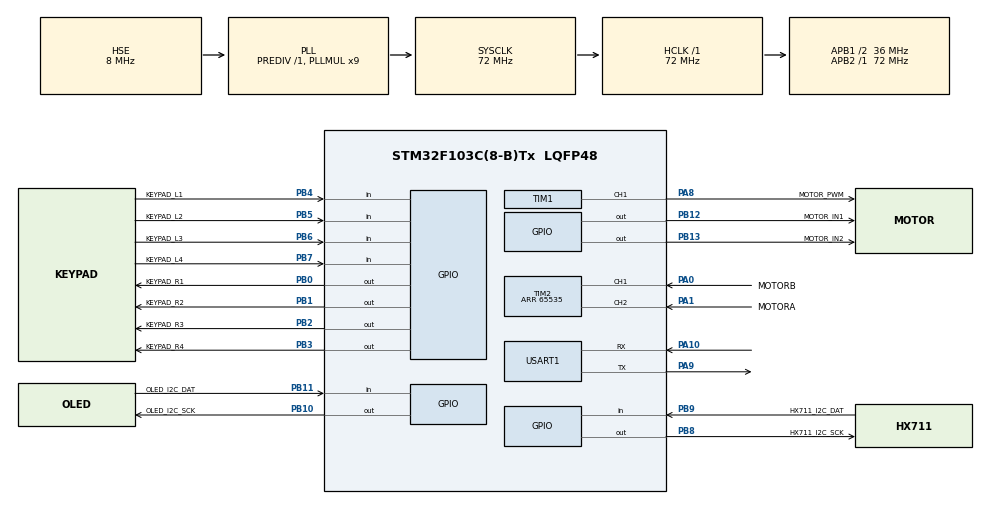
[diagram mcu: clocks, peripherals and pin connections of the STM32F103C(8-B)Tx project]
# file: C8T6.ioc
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Mcu.Family=STM32F1
Mcu.Name=STM32F103C(8-B)Tx
Mcu.Package=LQFP48
NVIC.PriorityGroup=NVIC_PRIORITYGROUP_4
PA0-WKUP.GPIO_Label=MOTORB
PA0-WKUP.Signal=S_TIM2_CH1_ETR
PA1.GPIO_Label=MOTORA
PA1.Signal=S_TIM2_CH2
PA10.Mode=Asynchronous
PA10.Signal=USART1_RX
PA13.Mode=Serial_Wire
PA13.Signal=SYS_JTMS-SWDIO
PA14.Mode=Serial_Wire
PA14.Signal=SYS_JTCK-SWCLK
PA8.GPIO_Label=MOTOR_PWM
PA8.Signal=S_TIM1_CH1
PA9.Mode=Asynchronous
PA9.Signal=USART1_TX
PB0.GPIO_Label=KEYPAD_R1
PB0.GPIO_PuPd=GPIO_PULLDOWN
PB0.Signal=GPIO_Output
PB1.GPIO_Label=KEYPAD_R2
PB1.GPIO_PuPd=GPIO_PULLDOWN
PB1.Signal=GPIO_Output
PB10.GPIO_Label=OLED_I2C_SCK
PB10.Signal=GPIO_Output
PB11.GPIO_Label=OLED_I2C_DAT 
PB11.GPIO_PuPd=GPIO_NOPULL
PB11.Signal=GPIO_Input
PB12.GPIO_Label=MOTOR_IN1
PB12.GPIO_PuPd=GPIO_PULLUP
PB12.Signal=GPIO_Output
PB13.GPIO_Label=MOTOR_IN2
PB13.GPIO_PuPd=GPIO_PULLUP
PB13.Signal=GPIO_Output
PB2.GPIO_Label=KEYPAD_R3
PB2.GPIO_PuPd=GPIO_PULLDOWN
PB2.Signal=GPIO_Output
PB3.GPIO_Label=KEYPAD_R4
PB3.GPIO_PuPd=GPIO_PULLDOWN
PB3.Signal=GPIO_Output
PB4.GPIO_Label=KEYPAD_L1
PB4.GPIO_PuPd=GPIO_PULLDOWN
PB4.Signal=GPIO_Input
PB5.GPIO_Label=KEYPAD_L2
PB5.GPIO_PuPd=GPIO_PULLDOWN
PB5.Signal=GPIO_Input
PB6.GPIO_Label=KEYPAD_L3
PB6.GPIO_PuPd=GPIO_PULLDOWN
PB6.Signal=GPIO_Input
PB7.GPIO_Label=KEYPAD_L4
PB7.GPIO_PuPd=GPIO_PULLDOWN
PB7.Signal=GPIO_Input
PB8.GPIO_Label=HX711_I2C_SCK 
PB8.Signal=GPIO_Output
PB9.GPIO_Label=HX711_I2C_DAT 
PB9.Signal=GPIO_Input
PD0-OSC_IN.Mode=HSE-External-Oscillator
PD0-OSC_IN.Signal=RCC_OSC_IN
PD1-OSC_OUT.Mode=HSE-External-Oscillator
PD1-OSC_OUT.Signal=RCC_OSC_OUT
ProjectManager.HeapSize=0x200
ProjectManager.StackSize=0x400
ProjectManager.TargetToolchain=MDK-ARM V5
RCC.AHBFreq_Value=72000000
RCC.APB1CLKDivider=RCC_HCLK_DIV2
RCC.APB1Freq_Value=36000000
RCC.APB1TimFreq_Value=72000000
RCC.APB2Freq_Value=72000000
RCC.APB2TimFreq_Value=72000000
RCC.HCLKFreq_Value=72000000
RCC.PLLMUL=RCC_PLL_MUL9
RCC.PLLSourceVirtual=RCC_PLLSOURCE_HSE
RCC.SYSCLKFreq_VALUE=72000000
RCC.SYSCLKSource=RCC_SYSCLKSOURCE_PLLCLK
RCC.USBFreq_Value=72000000
SH.S_TIM1_CH1.0=TIM1_CH1,PWM Generation1 CH1
SH.S_TIM2_CH1_ETR.0=TIM2_CH1,Encoder_Interface
SH.S_TIM2_CH2.0=TIM2_CH2,Encoder_Interface
TIM1.Channel-PWM\ Generation1\ CH1=TIM_CHANNEL_1
TIM1.Period=1000
TIM1.Prescaler=1
TIM2.EncoderMode=TIM_ENCODERMODE_TI12
TIM2.IC1Filter=6
TIM2.IC2Filter=6
TIM2.Period=65535
USART1.VirtualMode=VM_ASYNC
VP_TIM3_VS_ClockSourceINT.Mode=Internal
board=custom

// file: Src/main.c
/**
  ******************************************************************************
  * @file           : main.c
  * @brief          : Main program body
  ******************************************************************************
  ** This notice applies to any and all portions of this file
  * that are not between comment pairs USER CODE BEGIN and
  * USER CODE END. Other portions of this file, whether
  * inserted by the user or by software development tools
  * are owned by their respective copyright owners.
  *
  * COPYRIGHT(c) 2019 STMicroelectronics
  *
  * Redistribution and use in source and binary forms, with or without modification,
  * are permitted provided that the following conditions are met:
  *   1. Redistributions of source code must retain the above copyright notice,
  *      this list of conditions and the following disclaimer.
  *   2. Redistributions in binary form must reproduce the above copyright notice,
  *      this list of conditions and the following disclaimer in the documentation
  *      and/or other materials provided with the distribution.
  *   3. Neither the name of STMicroelectronics nor the names of its contributors
  *      may be used to endorse or promote products derived from this software
  *      without specific prior written permission.
  *
  * THIS SOFTWARE IS PROVIDED BY THE COPYRIGHT HOLDERS AND CONTRIBUTORS "AS IS"
  * AND ANY EXPRESS OR IMPLIED WARRANTIES, INCLUDING, BUT NOT LIMITED TO, THE
  * IMPLIED WARRANTIES OF MERCHANTABILITY AND FITNESS FOR A PARTICULAR PURPOSE ARE
  * DISCLAIMED. IN NO EVENT SHALL THE COPYRIGHT HOLDER OR CONTRIBUTORS BE LIABLE
  * FOR ANY DIRECT, INDIRECT, INCIDENTAL, SPECIAL, EXEMPLARY, OR CONSEQUENTIAL
  * DAMAGES (INCLUDING, BUT NOT LIMITED TO, PROCUREMENT OF SUBSTITUTE GOODS OR
  * SERVICES; LOSS OF USE, DATA, OR PROFITS; OR BUSINESS INTERRUPTION) HOWEVER
  * CAUSED AND ON ANY THEORY OF LIABILITY, WHETHER IN CONTRACT, STRICT LIABILITY,
  * OR TORT (INCLUDING NEGLIGENCE OR OTHERWISE) ARISING IN ANY WAY OUT OF THE USE
  * OF THIS SOFTWARE, EVEN IF ADVISED OF THE POSSIBILITY OF SUCH DAMAGE.
  *
  ******************************************************************************
  */
#include "main.h"
#include "stm32f1xx_hal.h"
#include "tim.h"
#include "usart.h"
#include "gpio.h"

/* USER CODE BEGIN Includes */
#include "oled.h"

/* USER CODE END Includes */

/* USER CODE BEGIN PV */
/* Private variables ---------------------------------------------------------*/

/* USER CODE END PV */

void SystemClock_Config(void);

/* USER CODE BEGIN PFP */
/* Private function prototypes -----------------------------------------------*/

/* USER CODE END PFP */

int main(void)
{

  /* MCU Configuration----------------------------------------------------------*/

  /* Reset of all peripherals, Initializes the Flash interface and the Systick. */
  HAL_Init();

  /* Configure the system clock */
  SystemClock_Config();

  /* Initialize all configured peripherals */
  MX_GPIO_Init();
  MX_TIM1_Init();
  MX_TIM2_Init();
  MX_USART1_UART_Init();
  MX_TIM3_Init();
  /* USER CODE BEGIN 2 */
		OLED_Init();			//初始化OLED
		OLED_Clear()  	;
  /* USER CODE END 2 */

  /* Infinite loop */
  /* USER CODE BEGIN WHILE */
  while (1)
  {
		OLED_ShowCHinese(0,0,0);//中
		OLED_ShowCHinese(18,0,1);//景
		OLED_ShowCHinese(36,0,2);//园
		OLED_ShowCHinese(54,0,3);//电
		OLED_ShowCHinese(72,0,4);//子
		OLED_ShowCHinese(90,0,5);//科
		OLED_ShowCHinese(108,0,6);//技
  /* USER CODE END WHILE */

  }

}

void SystemClock_Config(void)
{

  RCC_OscInitTypeDef RCC_OscInitStruct;
  RCC_ClkInitTypeDef RCC_ClkInitStruct;

    /**Initializes the CPU, AHB and APB busses clocks
    */
  RCC_OscInitStruct.OscillatorType = RCC_OSCILLATORTYPE_HSE;
  RCC_OscInitStruct.HSEState = RCC_HSE_ON;
  RCC_OscInitStruct.HSEPredivValue = RCC_HSE_PREDIV_DIV1;
  RCC_OscInitStruct.HSIState = RCC_HSI_ON;
  RCC_OscInitStruct.PLL.PLLState = RCC_PLL_ON;
  RCC_OscInitStruct.PLL.PLLSource = RCC_PLLSOURCE_HSE;
  RCC_OscInitStruct.PLL.PLLMUL = RCC_PLL_MUL9;
  if (HAL_RCC_OscConfig(&RCC_OscInitStruct) != HAL_OK)
  {
    _Error_Handler(__FILE__, __LINE__);
  }

    /**Initializes the CPU, AHB and APB busses clocks
    */
  RCC_ClkInitStruct.ClockType = RCC_CLOCKTYPE_HCLK|RCC_CLOCKTYPE_SYSCLK
                              |RCC_CLOCKTYPE_PCLK1|RCC_CLOCKTYPE_PCLK2;
  RCC_ClkInitStruct.SYSCLKSource = RCC_SYSCLKSOURCE_PLLCLK;
  RCC_ClkInitStruct.AHBCLKDivider = RCC_SYSCLK_DIV1;
  RCC_ClkInitStruct.APB1CLKDivider = RCC_HCLK_DIV2;
  RCC_ClkInitStruct.APB2CLKDivider = RCC_HCLK_DIV1;

  if (HAL_RCC_ClockConfig(&RCC_ClkInitStruct, FLASH_LATENCY_2) != HAL_OK)
  {
    _Error_Handler(__FILE__, __LINE__);
  }

    /**Configure the Systick interrupt time
    */
  HAL_SYSTICK_Config(HAL_RCC_GetHCLKFreq()/1000);

    /**Configure the Systick
    */
  HAL_SYSTICK_CLKSourceConfig(SYSTICK_CLKSOURCE_HCLK);

  /* SysTick_IRQn interrupt configuration */
  HAL_NVIC_SetPriority(SysTick_IRQn, 0, 0);
}

void _Error_Handler(char *file, int line)
{
  while(1)
  {
  }
}

/************************ (C) COPYRIGHT STMicroelectronics *****END OF FILE****/
